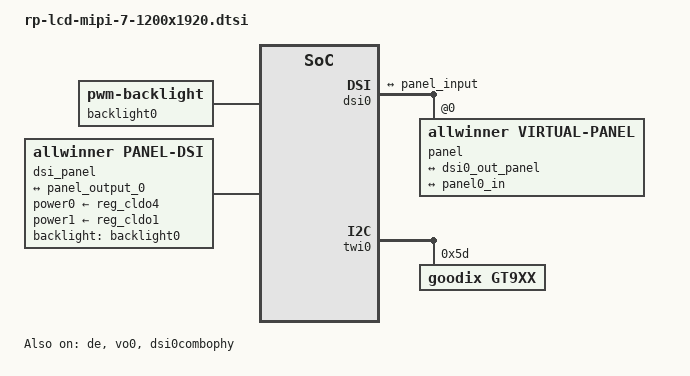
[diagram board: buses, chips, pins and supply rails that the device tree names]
/{
    backlight0: backlight@0 {
        compatible = "pwm-backlight";
        status = "okay";
        brightness-levels = <
              0   1   2   3   4   5   6   7
              8   9  10  11  12  13  14  15
             16  17  18  19  20  21  22  23
             24  25  26  27  28  29  30  31
             32  33  34  35  36  37  38  39
             40  41  42  43  44  45  46  47
             48  49  50  51  52  53  54  55
             56  57  58  59  60  61  62  63
             64  65  66  67  68  69  70  71
             72  73  74  75  76  77  78  79
             80  81  82  83  84  85  86  87
             88  89  90  91  92  93  94  95
             96  97  98  99 100 101 102 103
            104 105 106 107 108 109 110 111
            112 113 114 115 116 117 118 119
            120 121 122 123 124 125 126 127
            128 129 130 131 132 133 134 135
            136 137 138 139 140 141 142 143
            144 145 146 147 148 149 150 151
            152 153 154 155 156 157 158 159
            160 161 162 163 164 165 166 167
            168 169 170 171 172 173 174 175
            176 177 178 179 180 181 182 183
            184 185 186 187 188 189 190 191
            192 193 194 195 196 197 198 199
            200 201 202 203 204 205 206 207
            208 209 210 211 212 213 214 215
            216 217 218 219 220 221 222 223
            224 225 226 227 228 229 230 231
            232 233 234 235 236 237 238 239
            240 241 242 243 244 245 246 247
            248 249 250 251 252 253 254 255>;
        default-brightness-level = <200>;
        // pwms = <&pwm2 0 50000 0>; // config in lcd-gpio-xxx.dtsi
    };

    dsi_panel: dsi_panel@0 {
        compatible = "allwinner,panel-dsi";
        status = "okay";
        reg = <0>;
        power0-supply = <&reg_cldo4>;
        power1-supply = <&reg_cldo1>;

        // reset-gpios = <&pio PJ 17 GPIO_ACTIVE_HIGH>;   // config in lcd-gpio-xxx.dtsi
        // enable0-gpios = <&pio PJ 16 GPIO_ACTIVE_HIGH>; // config in lcd-gpio-xxx.dtsi
        power-delay-ms = <20>;
        enable-delay-ms = <20>;
        reset-num = <1>;
        reset-delay-ms = <20>;

        backlight = <&backlight0>;
        dsi,flags = <MIPI_DSI_MODE_VIDEO>;
        dsi,lanes = <4>;
        dsi,format = <0>; //MIPI_DSI_FMT_RGB888
        panel-init-sequence = [
            39 78 03 b7 50 00
            39 78 03 b8 00 00
            39 78 03 b9 00 00
            39 78 03 ba 14 42
            39 78 03 bb 03 00
            39 78 03 b9 01 00
            39 78 03 de 03 00
            39 78 03 c9 02 23

            39 78 02 b0 00
            39 78 06 14 08 b0 00 22 00
            39 78 02 b4 0c
            39 78 03 b6 3a d3
            39 78 02 51 e6
            39 78 02 53 2c

            05 78 01 29
            05 78 01 11

            39 78 03 b7 50 00
            39 78 03 b8 00 00
            39 78 03 b9 00 00
            39 78 03 ba 8c 83
            39 78 03 bb 03 00
            39 78 03 b9 01 00
            39 78 03 c9 02 23
            39 78 03 ca 01 23
            39 78 03 cb 10 05
            39 78 03 cc 05 10
            39 78 03 d0 00 00

            39 78 03 b6 03 00
            39 78 03 de 03 00
            39 78 03 d6 05 00
            39 78 03 b7 4b 02

            05 78 01 2c

            39 78 03 b6 03 00
            39 78 03 de 03 00
            39 78 03 d6 05 00
            39 78 03 b7 4b 02

            05 78 01 2c

        ];

        panel-exit-sequence = [
            05 00 01 28
            05 00 01 10
        ];

        display-timings {
            native-mode = <&dsi0_timing0>;

            dsi0_timing0: timing0 {
                clock-frequency = <148000000>; /* pixel clock */
                hactive      = <1200>;
                hback-porch  = <30>;
                hfront-porch = <60>;
                hsync-len    = <4>;

                vactive      = <1920>;
                vback-porch  = <16>;
                vfront-porch = <16>;
                vsync-len    = <2>;
            };
        };
        port {
            panel0_in: endpoint@0 {
                reg = <0>;
                    remote-endpoint = <&panel_output_0>;
            };
        };
    };
};

&lvds0 {
    status = "disabled";
};

&dsi0 {
    status = "okay";
    pinctrl-0 = <&dsi0_4lane_pins_a>;
    pinctrl-1 = <&dsi0_4lane_pins_b>;
    pinctrl-names = "active","sleep";
    ports {
        dsi0_out: port@1{
            dsi0_out_panel: endpoint {
                remote-endpoint = <&panel_input>;
            };
        };
    };
    panel: panel@0 {
        compatible = "allwinner,virtual-panel";
        status = "okay";
        reg = <0>;
        ports {
            panel_in: port@0 {
                reg = <0>;
                panel_input: endpoint@0 {
                    reg = <0>;
                    remote-endpoint = <&dsi0_out_panel>;
                };
            };
            panel_out: port@1 {
                reg = <1>;
                panel_output_0: endpoint@0 {
                    reg = <0>;
                    remote-endpoint = <&panel0_in>;
                };
            };
        };
    };
};

&de {
    chn_cfg_mode = <3>;
    status = "okay";
};

&vo0 {
    status = "okay";
};

&dsi0combophy {
    status = "okay";
};


&twi0 {
    status = "okay";

    gt9xx: gt9xx@5d {
    };
};

&gt9xx {
    compatible = "goodix,gt9xx";
    reg = <0x5d>;
    status = "okay";
    gtp_resolution_x = <1200>;
    gtp_resolution_y = <1920>;
    gtp_int_tarigger = <1>;
    gtp_change_x2y = <0>;
    gtp_overturn_x = <0>;
    gtp_overturn_y = <0>;
    gtp_send_cfg = <1>;
    gtp_touch_wakeup = <1>;
    gtp_touch_back = <1>;

    /*
    our gpio pin config in lcd-gpio-xxx.dtsi
    goodix_rst_gpio = <&pio PB 6 GPIO_ACTIVE_HIGH>;
    goodix_irq_gpio = <&pio PB 7 IRQ_TYPE_EDGE_RISING>;
*/

    goodix,cfg-group0 = [   //sensor id 0 for new tp
        44 B0 04 80 07 05 45 00 02 08 28
        08 46 32 03 05 00 00 00 00 00 00
        00 00 00 00 00 8C 2C 0E B0 B2 B2
        04 00 00 00 20 03 1C 00 01 00 00
        00 00 00 32 00 00 00 96 D2 94 D5
        02 00 00 00 04 8D 9B 00 85 A6 00
        7F B1 00 79 BD 00 73 CB 00 73 00
        00 00 00 00 00 00 00 00 00 00 00
        00 00 00 00 00 00 00 00 00 00 00
        00 00 00 00 00 00 00 00 00 00 00
        00 00 02 04 06 08 0A 0C 0E 10 12
        14 16 18 1A 1C FF FF FF FF FF FF
        FF FF FF FF FF FF FF FF FF FF 00
        02 04 06 08 0A 0C 0F 10 12 13 14
        28 26 24 22 21 20 1F 1E 1D 1C 18
        16 FF FF FF FF FF 00 00 00 00 00
        00 00 00 00 00 00 00 00 34 01
    ];
   //new touch for sensor_id5
    goodix,cfg-group2 = [    //sensor id 2 for new tp
        44 B0 04 80 07 05 45 00 02 08 28
        08 46 32 03 05 00 00 00 00 00 00
        00 00 00 00 00 8C 2C 0E B0 B2 B2
        04 00 00 00 20 03 1C 00 01 00 00
        00 00 00 32 00 00 00 96 D2 94 D5
        02 00 00 00 04 8D 9B 00 85 A6 00
        7F B1 00 79 BD 00 73 CB 00 73 00
        00 00 00 00 00 00 00 00 00 00 00
        00 00 00 00 00 00 00 00 00 00 00
        00 00 00 00 00 00 00 00 00 00 00
        00 00 02 04 06 08 0A 0C 0E 10 12
        14 16 18 1A 1C FF FF FF FF FF FF
        FF FF FF FF FF FF FF FF FF FF 00
        02 04 06 08 0A 0C 0F 10 12 13 14
        28 26 24 22 21 20 1F 1E 1D 1C 18
        16 FF FF FF FF FF 00 00 00 00 00
        00 00 00 00 00 00 00 00 34 01
    ];
    goodix,cfg-group5 = [
        5C B0 04 80 07 05 45 00 02 08
        28 08 46 32 03 05 00 00 00 00
        00 00 00 00 00 00 00 8C 2C 0E
        22 24 BB 0A 00 00 02 01 03 1C
        00 01 00 00 00 00 00 32 00 00
        00 14 46 94 C5 02 00 00 00 04
        E3 16 00 B4 1D 00 8D 25 00 72
        30 00 5D 3E 00 5D 00 00 00 00
        00 00 00 00 00 00 00 00 00 00
        00 00 00 00 00 00 00 00 00 00
        00 00 00 00 00 00 00 00 00 00
        00 00 02 04 06 08 0A 0C 0E 10
        12 14 16 18 1A 1C FF FF FF FF
        FF FF FF FF FF FF FF FF FF FF
        FF FF 00 02 04 06 08 0A 0C 0F
        10 12 13 14 28 26 24 22 21 20
        1F 1E 1D 1C 18 16 FF FF FF FF
        FF 00 00 00 00 00 00 00 00 00
        00 00 00 00 B8 01
    ];
};

